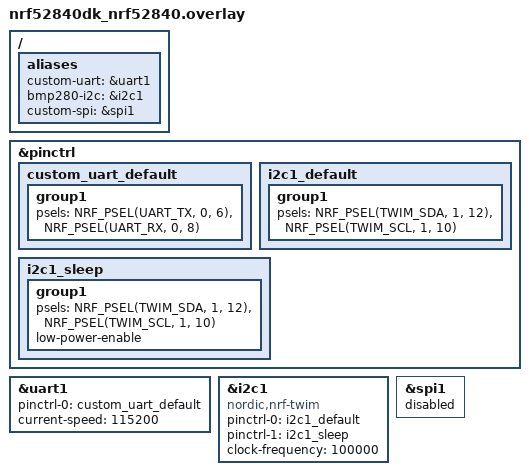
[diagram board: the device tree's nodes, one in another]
/* SPDX-License-Identifier: Apache-2.0 */

/ {
	aliases {
		custom-uart = &uart1;
		bmp280-i2c = &i2c1;
		custom-spi = &spi1;
	};
};

&pinctrl {
	custom_uart_default: custom_uart_default {
		group1 {
			psels = <NRF_PSEL(UART_TX, 0, 6)>,
				<NRF_PSEL(UART_RX, 0, 8)>;
		};
	};

	i2c1_default: i2c1_default {
		group1 {
			psels = <NRF_PSEL(TWIM_SDA, 1, 12)>,
				<NRF_PSEL(TWIM_SCL, 1, 10)>;
		};
	};

	i2c1_sleep: i2c1_sleep {
		group1 {
			psels = <NRF_PSEL(TWIM_SDA, 1, 12)>,
				<NRF_PSEL(TWIM_SCL, 1, 10)>;
			low-power-enable;
		};
	};
};

&uart1 {
    pinctrl-0 = <&custom_uart_default>;
    current-speed = <115200>;
    status = "okay";
};

&i2c1 {
	compatible = "nordic,nrf-twim";
	pinctrl-0 = <&i2c1_default>;
	pinctrl-1 = <&i2c1_sleep>;
	pinctrl-names = "default" , "sleep" ;
	clock-frequency = <100000>;
	status = "okay";

	// hrbo_sensor: hrbo_sensor@62 {
	// 	compatible = "maxim,maxm86161";
	// 	reg = <0x62>;
	// 	label = "HRBO_SENSOR";
	// 	status = "disabled";
	// };

	// aht20_sensor: aht20_sensor@38 {
	// 	compatible = "asair,aht20";
	// 	reg = <0x38>;
	// 	label = "AHT20_SENSOR";
	// 	status = "okay";
	// };

	// bmp280_sensor: bmp280_sensor@77 {
	// 	compatible = "bosch,bmp280";
	// 	reg = <0x77>;
	// 	label = "BMP280_SENSOR";
	// 	status = "okay";
	// };
};

&spi1 {
	status = "disabled";
};

